AUTOSAR XML (schema 4-1-1)
package /Door
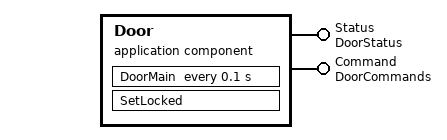
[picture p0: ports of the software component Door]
  application sw component type Door
    provide port Status: provided-interface=DoorStatus
    provide port Command: provided-interface=DoorCommands
    behavior DoorInternals: handle-termination-and-restart=NO-SUPPORT
      timing event timingEvent_0_1: start-on-event=DoorMain, period=0.1
      operation invoked event Command_SetLock: start-on-event=SetLocked, operation=Command.SetLock
      runnable DoorMain
        data-write-access:
          access dataWriteAccess_DoorMain_Status_Locked: accessed-variable=Status.Locked
          access dataWriteAccess_DoorMain_Status_Open: accessed-variable=Status.Open
      runnable SetLocked
  swc implementation DoorImplementation: programming-language=C, vendor-id=0, behavior=DoorInternals
    code-descriptors:
      code src: artifact-descriptors=autosar-engineering-object={short-label=artifactDescriptor, category=artifactDescriptorCategory}
    resource consumption resourceConsumption
